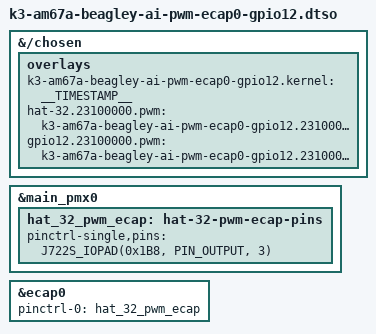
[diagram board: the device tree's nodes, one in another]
// SPDX-License-Identifier: GPL-2.0-only OR MIT
/*
 * DT Overlay for GPIO12 ecap0 connections within the expansion header.
 *
 * Copyright (C) 2023 Texas Instruments Incorporated - https://www.ti.com/
 *
 */

/dts-v1/;
/plugin/;

#include <dt-bindings/gpio/gpio.h>
#include "k3-pinctrl.h"

/*
 * Helper to show loaded overlays under: /proc/device-tree/chosen/overlays/
*/
&{/chosen} {
	overlays {
		k3-am67a-beagley-ai-pwm-ecap0-gpio12.kernel = __TIMESTAMP__;
		hat-32.23100000.pwm = "k3-am67a-beagley-ai-pwm-ecap0-gpio12.23100000.0.GPIO12";
		gpio12.23100000.pwm = "k3-am67a-beagley-ai-pwm-ecap0-gpio12.23100000.0.GPIO12";
	};
};

&main_pmx0 {
	hat_32_pwm_ecap: hat-32-pwm-ecap-pins {
		pinctrl-single,pins = <
			J722S_IOPAD(0x1B8, PIN_OUTPUT, 3) /* (C20) SPI0_CS1.ECAP0_IN_APWM_OUT */
		>;
	};
};

&ecap0 {
	pinctrl-names = "default";
	pinctrl-0 = <&hat_32_pwm_ecap>;
	status = "okay";
};
